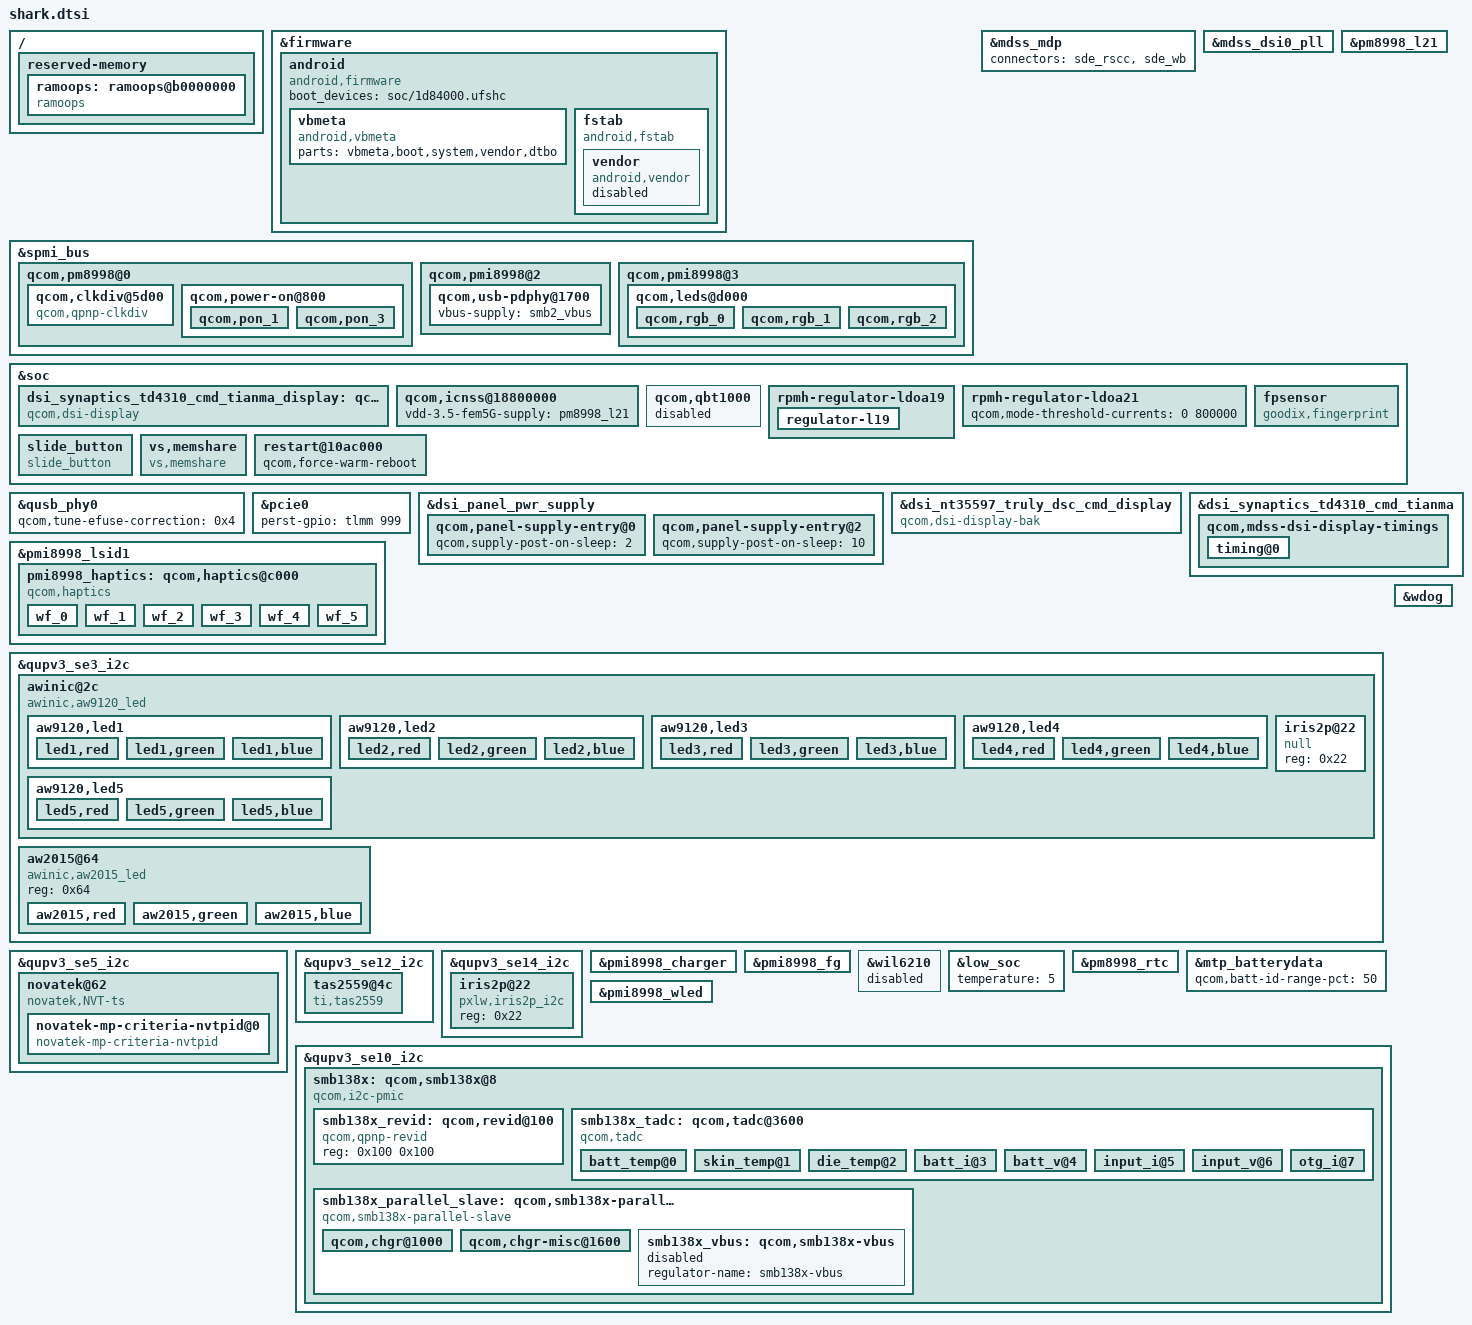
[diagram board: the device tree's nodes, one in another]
/*
 * Copyright (c) 2017, The Linux Foundation. All rights reserved.
 * Copyright (C) 2019 XiaoMi, Inc.
 *
 * This program is free software; you can redistribute it and/or modify
 * it under the terms of the GNU General Public License version 2 and
 * only version 2 as published by the Free Software Foundation.
 *
 * This program is distributed in the hope that it will be useful,
 * but WITHOUT ANY WARRANTY; without even the implied warranty of
 * MERCHANTABILITY or FITNESS FOR A PARTICULAR PURPOSE.  See the
 * GNU General Public License for more details.
 */

#include <dt-bindings/interrupt-controller/irq.h>
#include <dt-bindings/msm/power-on.h>

#include "dsi-panel-synaptics-td4310-video.dtsi"
#include "dsi-panel-synaptics-td4310-cmd.dtsi"

#include "shark-audio-overlay.dtsi"
#include "shark-pinctrl.dtsi"

/ {
	reserved-memory {
		ramoops: ramoops@b0000000 {
			compatible = "ramoops";
			reg = <0 0xb0000000 0 0x00400000>;
			record-size = <0x40000>; /*256x1024*/
			console-size = <0x40000>;
			ftrace-size = <0x40000>;
			pmsg-size = <0x200000>;
			ecc-size = <0x0>;
		};
	};
};

&firmware {
	android {
		compatible = "android,firmware";
		boot_devices = "soc/1d84000.ufshc";
		vbmeta {
			compatible = "android,vbmeta";
			parts = "vbmeta,boot,system,vendor,dtbo";
		};

		fstab {
			compatible = "android,fstab";
			vendor {
				compatible = "android,vendor";
				dev = "/dev/block/platform/soc/1d84000.ufshc/by-name/vendor";
				type = "ext4";
				mnt_flags = "ro,barrier=1,discard";
				fsmgr_flags = "wait,slotselect,avb";
				status = "disabled";
			};
		};
	};
};

&spmi_bus {
	qcom,pm8998@0 {
		qcom,clkdiv@5d00 {
			compatible = "qcom,qpnp-clkdiv";
			reg = <0x5d00 0x100>;
			#clock-cells = <1>;
			qcom,cxo-freq = <19200000>;
			qcom,clkdiv-id = <3>;
			qcom,clkdiv-init-freq = <19200000>;
		};

		qcom,power-on@800 {
			interrupt-names = "kpdpwr", "resin", "kpdpwr-bark",
							  "resin-bark", "kpdpwr-resin-bark";
			interrupts = <0x0 0x8 0x0 IRQ_TYPE_NONE>,
						 <0x0 0x8 0x1 IRQ_TYPE_NONE>,
						 <0x0 0x8 0x3 IRQ_TYPE_NONE>,
						 <0x0 0x8 0x4 IRQ_TYPE_NONE>,
						 <0x0 0x8 0x5 IRQ_TYPE_NONE>;
			
			qcom,pon_1 {
				qcom,support-reset = <1>;
 				qcom,s1-timer = <6720>;
 				qcom,s2-timer = <2000>;
 				qcom,s2-type = <PON_POWER_OFF_HARD_RESET>;
 				qcom,use-bark;
			};

			qcom,pon_3 {
				qcom,s1-timer = <4480>;
 				qcom,s2-timer = <1000>;
 				qcom,s2-type = <PON_POWER_OFF_DVDD_SHUTDOWN>;
			};
		};
	};

	/* shark vbus change to pmi supply */
	qcom,pmi8998@2 {
		qcom,usb-pdphy@1700 {
			vbus-supply = <&smb2_vbus>;
		};
	};

	qcom,pmi8998@3 {
		qcom,leds@d000 {
			qcom,rgb_0 {
				linux,name = "red";
				qcom,default-state = "off";
				linux,default-trigger = "none";
				qcom,start-idx = <0>;
				qcom,idx-len = <48>;
				qcom,turn-off-delay-ms = <500>;
				qcom,duty-pcts =
					[00 00 01 02 03 04 05 06 07 08 09 08 07 06 05 04 03 02 01 00 00 00 00 00
					00 00 00 00 00 00 00 00 00 00 00 00 00 00 00 00 00 00 00 00 00 00 00 00];
				qcom,use-blink;
				qcom,lut-flags = <3>;
				qcom,pause-lo = <0>;
				qcom,pause-hi = <0>;
				qcom,ramp-step-ms = <100>;
				qcom,pwm-us = <1000>;
				qcom,max-current = <12>;
			};

			qcom,rgb_1 {
				linux,name = "green";
				qcom,default-state = "off";
				linux,default-trigger = "none";
				qcom,start-idx = <0>;
				qcom,idx-len = <48>;
				qcom,turn-off-delay-ms = <500>;
				qcom,duty-pcts =
					[00 00 01 02 03 04 05 06 07 08 09 08 07 06 05 04 03 02 01 00 00 00 00 00
					00 00 00 00 00 00 00 00 00 00 00 00 00 00 00 00 00 00 00 00 00 00 00 00];
				qcom,use-blink;
				qcom,lut-flags = <3>;
				qcom,pause-lo = <0>;
				qcom,pause-hi = <0>;
				qcom,ramp-step-ms = <100>;
				qcom,pwm-us = <1000>;
				qcom,max-current = <12>;
			};

			qcom,rgb_2 {
				linux,name = "blue";
				qcom,default-state = "off";
				linux,default-trigger = "none";
				qcom,start-idx = <0>;
				qcom,idx-len = <48>;
				qcom,turn-off-delay-ms = <500>;
				qcom,duty-pcts =
					[00 00 01 02 03 04 05 06 07 08 09 08 07 06 05 04 03 02 01 00 00 00 00 00
					00 00 00 00 00 00 00 00 00 00 00 00 00 00 00 00 00 00 00 00 00 00 00 00];
				qcom,use-blink;
				qcom,lut-flags = <3>;
				qcom,pause-lo = <0>;
				qcom,pause-hi = <0>;
				qcom,ramp-step-ms = <100>;
				qcom,pwm-us = <1000>;
				qcom,max-current = <12>;
			};
		};
	};
};

&mdss_mdp {
	connectors = <&sde_rscc &sde_wb>;
};

&mdss_dsi0_pll {
	qcom,ssc-frequency-hz = <30000>;
	qcom,ssc-ppm = <5000>;
};

&pm8998_l21 {
	regulator-min-microvolt = <3500000>;
	regulator-max-microvolt = <3500000>;
	qcom,init-voltage = <3500000>;
};

&soc {
	dsi_synaptics_td4310_cmd_tianma_display: qcom,dsi-display@29 {
		compatible = "qcom,dsi-display";
		label = "dsi_synap_cmd_tianma_display";
		qcom,display-type = "primary";
		qcom,dsi-ctrl = <&mdss_dsi0>;
		qcom,dsi-phy = <&mdss_dsi_phy0>;
		clocks = <&mdss_dsi0_pll BYTECLK_MUX_0_CLK>,
				<&mdss_dsi0_pll PCLK_MUX_0_CLK>, <&pm8998_div_clk3 0>;
		clock-names = "mux_byte_clk", "mux_pixel_clk", "div_clk3";
		pinctrl-names = "panel_active", "panel_suspend", "default";
		pinctrl-0 = <&sde_dsi_active &sde_te_active>;
		pinctrl-1 = <&sde_dsi_suspend &sde_te_suspend>;
		pinctrl-2 = <&clk_out_default>;
		qcom,dsi-panel = <&dsi_synaptics_td4310_cmd_tianma>;
		vddio-supply = <&pm8998_l14>;
		lab-supply = <&lab_regulator>;
		ibb-supply = <&ibb_regulator>;
	};

	qcom,icnss@18800000 {
		vdd-3.5-fem5G-supply = <&pm8998_l21>;
	};

	qcom,qbt1000 {
		status = "disabled";
	};

	rpmh-regulator-ldoa19 {
		regulator-l19 {
			regulator-max-microvolt = <3310000>;
			qcom,init-voltage = <3100000>;
			regulator-always-on;
		};
	};

	rpmh-regulator-ldoa21 {
		qcom,mode-threshold-currents = <0 800000>;
	};

	fpsensor {
		status = "ok";
		compatible = "goodix,fingerprint";
		vdd_io-supply  = <&pm8998_l19>;
		fp,gpio_rst    = <&tlmm 128 0x00>;
		fp,gpio_irq    = <&tlmm 121 0x00>;
		interrupt-parent = <&tlmm>;
		interrupts = <121 0x0>;
    };

	slide_button {
		compatible = "slide_button";

		pinctrl-names = "default";
		pinctrl-0 = <&slide_button_default>;

		slide-button,gpios = <&tlmm 119 0>;
		debounce-interval = <15>;
		slide-button,wakeup;
	};

	vs,memshare {
		compatible = "vs,memshare";
	};

	restart@10ac000 {
		qcom,force-warm-reboot;
	};
};

&qusb_phy0 {
	qcom,tune-efuse-correction = <0x4>;
};

&pcie0 {
	// hack
	perst-gpio = <&tlmm 999 0>;
};

&dsi_panel_pwr_supply {
	qcom,panel-supply-entry@0 {
		qcom,supply-post-on-sleep = <2>;
	};

	qcom,panel-supply-entry@2 {
		qcom,supply-post-on-sleep = <10>;
	};
};

&mdss_mdp {
	/delete-property/ qcom,sde-has-idle-pc;
};

&dsi_nt35597_truly_dsc_cmd_display {
	compatible = "qcom,dsi-display-bak";
	/delete-property/ qcom,dsi-display-active;
};

&dsi_synaptics_td4310_cmd_tianma_display {
	qcom,dsi-display-active;
};

&dsi_synaptics_td4310_cmd_tianma {
        qcom,mdss-dsi-t-clk-post = <0x0E>;
        qcom,mdss-dsi-t-clk-pre = <0x34>;
        qcom,panel-supply-entries = <&dsi_panel_pwr_supply>;
        qcom,mdss-dsi-bl-pmic-control-type = "bl_ctrl_wled";
        qcom,mdss-dsi-bl-min-level = <1>;
        qcom,mdss-dsi-bl-max-level = <4095>;
        qcom,mdss-brightness-max-level = <4095>;
        qcom,platform-te-gpio = <&tlmm 10 0>;
        qcom,platform-reset-gpio = <&tlmm 94 0>;
        qcom,dsp-reset-gpio = <&tlmm 51 0>;
        qcom,dsp-dsp_1v1 = <&tlmm 37 0>;
        qcom,mdss-dsi-mode-sel-gpio-state = "single_port";

        qcom,mdss-dsi-panel-status-check-mode = "reg_read";
        qcom,mdss-dsi-panel-status-command = [06 01 00 01 00 00 01 0a];
        qcom,mdss-dsi-panel-status-command-state = "dsi_hs_mode";
        qcom,mdss-dsi-panel-status-value = <0x9c>;
        qcom,mdss-dsi-panel-on-check-value = <0x9c>;
        qcom,mdss-dsi-panel-status-read-length = <1>;
		qcom,esd-check-enabled;

		qcom,mdss-dsi-display-timings {
			timing@0{
				qcom,mdss-dsi-panel-phy-timings = [00 22 08 09 25 23 09 09 06 03 04 00];
				qcom,display-topology = <1 0 1>,
										<1 0 2>;
				qcom,default-topology-index = <0>;
			};
		};
};

&pmi8998_lsid1 {
	pmi8998_haptics: qcom,haptics@c000 {
		compatible = "qcom,haptics";
		reg = <0xc000 0x100>;
		interrupts = <0x3 0xc0 0x0 IRQ_TYPE_EDGE_BOTH>,
				<0x3 0xc0 0x1 IRQ_TYPE_EDGE_BOTH>;
		interrupt-names = "hap-sc-irq", "hap-play-irq";

		qcom,vmax-mv = <2800>;
		qcom,ilim-ma = <800>;
		qcom,play-rate-us = <5252>;

		qcom,actuator-type = "lra";
		qcom,lra-resonance-sig-shape = "sine";
		qcom,lra-auto-resonance-mode = "qwd";
		qcom,lra-allow-variable-play-rate;
		qcom,lra-auto-resonance-disable;

		status = "ok";

		wf_0 {
			/* CLICK */
			qcom,effect-id = <0>;
			qcom,wf-vmax-mv = <2700>;
			qcom,wf-pattern = [7e 7e 7e];
			qcom,wf-brake-pattern = [01 00 01 00];
			qcom,lra-auto-resonance-disable;
			qcom,wf-play-rate-us = <4255>;
		};

		wf_1 {
			/* DOUBLE CLICK */
			qcom,effect-id = <1>;
			qcom,wf-vmax-mv = <2700>;
			qcom,wf-pattern = [7e 7e 02 02 02 02 02 02];
			qcom,wf-repeat-count = <2>;
			qcom,wf-s-repeat-count = <1>;
			qcom,lra-auto-resonance-disable;
			qcom,wf-play-rate-us = <4255>;
		};

		wf_2 {
			/* TICK */
			qcom,effect-id = <2>;
			qcom,wf-vmax-mv = <2600>;
			qcom,wf-pattern = [7e];
			qcom,wf-brake-pattern = [01 00 00 00];
			qcom,lra-auto-resonance-disable;
			qcom,wf-play-rate-us = <4255>;
		};

		wf_3 {
			/* THUD */
			qcom,effect-id = <3>;
			qcom,wf-vmax-mv = <2700>;
			qcom,wf-pattern = [7e 7e 7e];
			qcom,lra-auto-resonance-disable;
			qcom,wf-play-rate-us = <4255>;
		};

		wf_4 {
			/* POP */
			qcom,effect-id = <4>;
			qcom,wf-vmax-mv = <2600>;
			qcom,wf-pattern = [7e];
			qcom,wf-brake-pattern = [01 00 01 00];
			qcom,lra-auto-resonance-disable;
			qcom,wf-play-rate-us = <4255>;
		};

		wf_5 {
			/* HEAVY CLICK */
			qcom,effect-id = <5>;
			qcom,wf-vmax-mv = <3100>;
			qcom,wf-pattern = [7e 7e 7e 7e 02 02 7e 7e];
			qcom,lra-auto-resonance-disable;
			qcom,wf-play-rate-us = <4155>;
		};
	};
};

&qupv3_se3_i2c {
    status = "ok";
    awinic@2c {
        compatible = "awinic,aw9120_led";
        reg = <0x2c>;

        pinctrl-names = "awinic_pin_active",
						"awinic_pin_suspend";
        pinctrl-0 = <&aw9120_pdn_gpio_active>;
        pinctrl-1 = <&aw9120_pdn_gpio_suspend>;

		awinic,pdn-gpio = <&tlmm 39 0x00>;
        aw9120,pwm-freq = <245>;
        aw9120,dimming-mode = "loge";

        aw9120,led1 {
            led1,red {
                aw9120,name = "led1:red";
                aw9120,id = <0>;
                aw9120,max-brightness = <255>;
                aw9120,max-current = <17>;
            };
            led1,green {
                aw9120,name = "led1:green";
                aw9120,id = <1>;
                aw9120,max-brightness = <255>;
                aw9120,max-current = <17>;
            };
            led1,blue {
                aw9120,name = "led1:blue";
                aw9120,id = <2>;
                aw9120,max-brightness = <255>;
                aw9120,max-current = <17>;
            };
        };

        aw9120,led2 {
            led2,red {
                aw9120,name = "led2:red";
                aw9120,id = <3>;
                aw9120,max-brightness = <255>;
                aw9120,max-current = <17>;
            };

            led2,green {
                aw9120,name = "led2:green";
                aw9120,id = <4>;
                aw9120,max-brightness = <255>;
                aw9120,max-current = <17>;
            };

            led2,blue {
                aw9120,name = "led2:blue";
                aw9120,id = <5>;
                aw9120,max-brightness = <255>;
                aw9120,max-current = <17>;
            };
        };

        aw9120,led3 {
            led3,red {
                aw9120,name = "led3:red";
                aw9120,id = <6>;
                aw9120,max-brightness = <255>;
                aw9120,max-current = <17>;
            };

            led3,green {
                aw9120,name = "led3:green";
                aw9120,id = <7>;
                aw9120,max-brightness = <255>;
                aw9120,max-current = <17>;
            };
			
            led3,blue {
                aw9120,name = "led3:blue";
                aw9120,id = <15>;
                aw9120,max-brightness = <255>;
                aw9120,max-current = <17>;
            };
        };

        aw9120,led4 {
            led4,red {
                aw9120,name = "led4:red";
                aw9120,id = <9>;
                aw9120,max-brightness = <255>;
                aw9120,max-current = <17>;
            };

            led4,green {
                aw9120,name = "led4:green";
                aw9120,id = <10>;
                aw9120,max-brightness = <255>;
                aw9120,max-current = <17>;
            };

            led4,blue {
                aw9120,name = "led4:blue";
                aw9120,id = <11>;
                aw9120,max-brightness = <255>;
                aw9120,max-current = <17>;
            };
        };

        aw9120,led5 {
            led5,red {
                aw9120,name = "led5:red";
                aw9120,id = <12>;
                aw9120,max-brightness = <255>;
                aw9120,max-current = <17>;
            };

            led5,green {
                aw9120,name = "led5:green";
                aw9120,id = <13>;
                aw9120,max-brightness = <255>;
                aw9120,max-current = <17>;
            };

            led5,blue {
                aw9120,name = "led5:blue";
                aw9120,id = <14>;
                aw9120,max-brightness = <255>;
                aw9120,max-current = <17>;
            };
        };

        iris2p@22 {
                compatible = "null";
                reg = <0x22>;
        };
    };

	aw2015@64 {
		compatible = "awinic,aw2015_led";
		reg = <0x64>;

		aw2015,red {
			aw2015,name = "red";
			aw2015,id = <0>;
			aw2015,imax = <2>;
			aw2015,led-current = <255>;
			aw2015,max-brightness = <255>;
			aw2015,rise-time-ms = <6>;
			aw2015,hold-time-ms = <0>;
			aw2015,fall-time-ms = <6>;
			aw2015,off-time-ms = <4>;
		};

		aw2015,green {
			aw2015,name = "green";
			aw2015,id = <1>;
			aw2015,imax = <2>;
			aw2015,led-current = <255>;
			aw2015,max-brightness = <255>;
			aw2015,rise-time-ms = <6>;
			aw2015,hold-time-ms = <0>;
			aw2015,fall-time-ms = <6>;
			aw2015,off-time-ms = <4>;
		};

		aw2015,blue {
			aw2015,name = "blue";
			aw2015,id = <2>;
			aw2015,imax = <2>;
			aw2015,led-current = <255>;
			aw2015,max-brightness = <255>;
			aw2015,rise-time-ms = <6>;
			aw2015,hold-time-ms = <0>;
			aw2015,fall-time-ms = <6>;
			aw2015,off-time-ms = <4>;
		};
	};
};


&qupv3_se5_i2c {
	status = "okay";

	novatek@62 {
		compatible = "novatek,NVT-ts";
		reg = <0x62>;
		status = "ok";

		avdd-supply = <&pm8998_l14>;

		novatek,reset-gpio = <&tlmm 89 0x00>;
		novatek,irq-gpio = <&tlmm 125 0x2001>;

		novatek,button-keys = <0x244 158>;

		novatek-mp-criteria-nvtpid@0 {
			#address-cells = <1>;
			#size-cells = <0>;
			compatible = "novatek-mp-criteria-nvtpid";

			IC_X_CFG_SIZE = <18>;
			IC_Y_CFG_SIZE = <32>;
			IC_KEY_CFG_SIZE = <4>;
			X_Channel = <18>;
			Y_Channel = <30>;
			AIN_X = <17 16 15 14 13 12 11 10 9 8 7 6 5 4 3 2 1 0>;
			AIN_Y = <0xFF 0xFF 29 28 27 26 25 24 23 22 21 20 19 18 17 16 15
								14 13 12 11 10 9 8 7 6 5 4 3 2 1 0>;
			AIN_KEY = <0 1 2 0xFF>;

			PS_Config_Lmt_Short_Rawdata_P = <20000>;
			PS_Config_Lmt_Short_Rawdata_N = <11550>;
			PS_Config_Lmt_Key_Short_Rawdata_P = <20000>;
			PS_Config_Lmt_Key_Short_Rawdata_N = <11550>;
			PS_Config_Lmt_Short_Diff_P = <6300>;
			PS_Config_Lmt_Short_Diff_N = <0>;
			PS_Config_Lmt_Key_Short_Diff_P = <6300>;
			PS_Config_Lmt_Key_Short_Diff_N = <0>;
			PS_Config_Lmt_Short_Base_P = <2000>;
			PS_Config_Lmt_Short_Base_N = <(-2000)>;
			PS_Config_Lmt_Key_Short_Base_P = <2000>;
			PS_Config_Lmt_Key_Short_Base_N = <(-2000)>;

			PS_Config_Lmt_Open_Rawdata_P = <
				13000 13000 13000 13000 13000 13000 13000 13000 13000 13000 13000 13000 13000 13000 13000 13000 13000 13000
				13000 13000 13000 13000 13000 13000 13000 13000 13000 13000 13000 13000 13000 13000 13000 13000 13000 13000
				13000 13000 13000 13000 13000 13000 13000 13000 13000 13000 13000 13000 13000 13000 13000 13000 13000 13000
				13000 13000 13000 13000 13000 13000 13000 13000 13000 13000 13000 13000 13000 13000 13000 13000 13000 13000
				13000 13000 13000 13000 13000 13000 13000 13000 13000 13000 13000 13000 13000 13000 13000 13000 13000 13000
				13000 13000 13000 13000 13000 13000 13000 13000 13000 13000 13000 13000 13000 13000 13000 13000 13000 13000
				13000 13000 13000 13000 13000 13000 13000 13000 13000 13000 13000 13000 13000 13000 13000 13000 13000 13000
				13000 13000 13000 13000 13000 13000 13000 13000 13000 13000 13000 13000 13000 13000 13000 13000 13000 13000
				13000 13000 13000 13000 13000 13000 13000 13000 13000 13000 13000 13000 13000 13000 13000 13000 13000 13000
				13000 13000 13000 13000 13000 13000 13000 13000 13000 13000 13000 13000 13000 13000 13000 13000 13000 13000
				13000 13000 13000 13000 13000 13000 13000 13000 13000 13000 13000 13000 13000 13000 13000 13000 13000 13000
				13000 13000 13000 13000 13000 13000 13000 13000 13000 13000 13000 13000 13000 13000 13000 13000 13000 13000
				13000 13000 13000 13000 13000 13000 13000 13000 13000 13000 13000 13000 13000 13000 13000 13000 13000 13000
				13000 13000 13000 13000 13000 13000 13000 13000 13000 13000 13000 13000 13000 13000 13000 13000 13000 13000
				13000 13000 13000 13000 13000 13000 13000 13000 13000 13000 13000 13000 13000 13000 13000 13000 13000 13000
				13000 13000 13000 13000 13000 13000 13000 13000 13000 13000 13000 13000 13000 13000 13000 13000 13000 13000
				13000 13000 13000 13000 13000 13000 13000 13000 13000 13000 13000 13000 13000 13000 13000 13000 13000 13000
				13000 13000 13000 13000 13000 13000 13000 13000 13000 13000 13000 13000 13000 13000 13000 13000 13000 13000
				13000 13000 13000 13000 13000 13000 13000 13000 13000 13000 13000 13000 13000 13000 13000 13000 13000 13000
				13000 13000 13000 13000 13000 13000 13000 13000 13000 13000 13000 13000 13000 13000 13000 13000 13000 13000
				13000 13000 13000 13000 13000 13000 13000 13000 13000 13000 13000 13000 13000 13000 13000 13000 13000 13000
				13000 13000 13000 13000 13000 13000 13000 13000 13000 13000 13000 13000 13000 13000 13000 13000 13000 13000
				13000 13000 13000 13000 13000 13000 13000 13000 13000 13000 13000 13000 13000 13000 13000 13000 13000 13000
				13000 13000 13000 13000 13000 13000 13000 13000 13000 13000 13000 13000 13000 13000 13000 13000 13000 13000
				13000 13000 13000 13000 13000 13000 13000 13000 13000 13000 13000 13000 13000 13000 13000 13000 13000 13000
				13000 13000 13000 13000 13000 13000 13000 13000 13000 13000 13000 13000 13000 13000 13000 13000 13000 13000
				13000 13000 13000 13000 13000 13000 13000 13000 13000 13000 13000 13000 13000 13000 13000 13000 13000 13000
				13000 13000 13000 13000 13000 13000 13000 13000 13000 13000 13000 13000 13000 13000 13000 13000 13000 13000
				13000 13000 13000 13000 13000 13000 13000 13000 13000 13000 13000 13000 13000 13000 13000 13000 13000 13000
				13000 13000 13000 13000 13000 13000 13000 13000 13000 13000 13000 13000 13000 13000 13000 13000 13000 13000
				13000 13000 13000>;

			PS_Config_Lmt_Open_Rawdata_N = <
				6500 6500 6500 6500 6500 6500 6500 6500 6500 6500 6500 6500 6500 6500 6500 6500 6500 6500
				6500 6500 6500 6500 6500 6500 6500 6500 6500 6500 6500 6500 6500 6500 6500 6500 6500 6500
				6500 6500 6500 6500 6500 6500 6500 6500 6500 6500 6500 6500 6500 6500 6500 6500 6500 6500
				6500 6500 6500 6500 6500 6500 6500 6500 6500 6500 6500 6500 6500 6500 6500 6500 6500 6500
				6500 6500 6500 6500 6500 6500 6500 6500 6500 6500 6500 6500 6500 6500 6500 6500 6500 6500
				6500 6500 6500 6500 6500 6500 6500 6500 6500 6500 6500 6500 6500 6500 6500 6500 6500 6500
				6500 6500 6500 6500 6500 6500 6500 6500 6500 6500 6500 6500 6500 6500 6500 6500 6500 6500
				6500 6500 6500 6500 6500 6500 6500 6500 6500 6500 6500 6500 6500 6500 6500 6500 6500 6500
				6500 6500 6500 6500 6500 6500 6500 6500 6500 6500 6500 6500 6500 6500 6500 6500 6500 6500
				6500 6500 6500 6500 6500 6500 6500 6500 6500 6500 6500 6500 6500 6500 6500 6500 6500 6500
				6500 6500 6500 6500 6500 6500 6500 6500 6500 6500 6500 6500 6500 6500 6500 6500 6500 6500
				6500 6500 6500 6500 6500 6500 6500 6500 6500 6500 6500 6500 6500 6500 6500 6500 6500 6500
				6500 6500 6500 6500 6500 6500 6500 6500 6500 6500 6500 6500 6500 6500 6500 6500 6500 6500
				6500 6500 6500 6500 6500 6500 6500 6500 6500 6500 6500 6500 6500 6500 6500 6500 6500 6500
				6500 6500 6500 6500 6500 6500 6500 6500 6500 6500 6500 6500 6500 6500 6500 6500 6500 6500
				6500 6500 6500 6500 6500 6500 6500 6500 6500 6500 6500 6500 6500 6500 6500 6500 6500 6500
				6500 6500 6500 6500 6500 6500 6500 6500 6500 6500 6500 6500 6500 6500 6500 6500 6500 6500
				6500 6500 6500 6500 6500 6500 6500 6500 6500 6500 6500 6500 6500 6500 6500 6500 6500 6500
				6500 6500 6500 6500 6500 6500 6500 6500 6500 6500 6500 6500 6500 6500 6500 6500 6500 6500
				6500 6500 6500 6500 6500 6500 6500 6500 6500 6500 6500 6500 6500 6500 6500 6500 6500 6500
				6500 6500 6500 6500 6500 6500 6500 6500 6500 6500 6500 6500 6500 6500 6500 6500 6500 6500
				6500 6500 6500 6500 6500 6500 6500 6500 6500 6500 6500 6500 6500 6500 6500 6500 6500 6500
				6500 6500 6500 6500 6500 6500 6500 6500 6500 6500 6500 6500 6500 6500 6500 6500 6500 6500
				6500 6500 6500 6500 6500 6500 6500 6500 6500 6500 6500 6500 6500 6500 6500 6500 6500 6500
				6500 6500 6500 6500 6500 6500 6500 6500 6500 6500 6500 6500 6500 6500 6500 6500 6500 6500
				6500 6500 6500 6500 6500 6500 6500 6500 6500 6500 6500 6500 6500 6500 6500 6500 6500 6500
				6500 6500 6500 6500 6500 6500 6500 6500 6500 6500 6500 6500 6500 6500 6500 6500 6500 6500
				6500 6500 6500 6500 6500 6500 6500 6500 6500 6500 6500 6500 6500 6500 6500 6500 6500 6500
				6500 6500 6500 6500 6500 6500 6500 6500 6500 6500 6500 6500 6500 6500 6500 6500 6500 6500
				6500 6500 6500 6500 6500 6500 6500 6500 6500 6500 6500 6500 6500 6500 6500 6500 6500 6500
				6500 6500 6500>;

			PS_Config_Lmt_FW_Rawdata_P = <
				2000 2000 2000 2000 2000 2000 2000 2000 2000 2000 2000 2000 2000 2000 2000 2000 2000 2000
				2000 2000 2000 2000 2000 2000 2000 2000 2000 2000 2000 2000 2000 2000 2000 2000 2000 2000
				2000 2000 2000 2000 2000 2000 2000 2000 2000 2000 2000 2000 2000 2000 2000 2000 2000 2000
				2000 2000 2000 2000 2000 2000 2000 2000 2000 2000 2000 2000 2000 2000 2000 2000 2000 2000
				2000 2000 2000 2000 2000 2000 2000 2000 2000 2000 2000 2000 2000 2000 2000 2000 2000 2000
				2000 2000 2000 2000 2000 2000 2000 2000 2000 2000 2000 2000 2000 2000 2000 2000 2000 2000
				2000 2000 2000 2000 2000 2000 2000 2000 2000 2000 2000 2000 2000 2000 2000 2000 2000 2000
				2000 2000 2000 2000 2000 2000 2000 2000 2000 2000 2000 2000 2000 2000 2000 2000 2000 2000
				2000 2000 2000 2000 2000 2000 2000 2000 2000 2000 2000 2000 2000 2000 2000 2000 2000 2000
				2000 2000 2000 2000 2000 2000 2000 2000 2000 2000 2000 2000 2000 2000 2000 2000 2000 2000
				2000 2000 2000 2000 2000 2000 2000 2000 2000 2000 2000 2000 2000 2000 2000 2000 2000 2000
				2000 2000 2000 2000 2000 2000 2000 2000 2000 2000 2000 2000 2000 2000 2000 2000 2000 2000
				2000 2000 2000 2000 2000 2000 2000 2000 2000 2000 2000 2000 2000 2000 2000 2000 2000 2000
				2000 2000 2000 2000 2000 2000 2000 2000 2000 2000 2000 2000 2000 2000 2000 2000 2000 2000
				2000 2000 2000 2000 2000 2000 2000 2000 2000 2000 2000 2000 2000 2000 2000 2000 2000 2000
				2000 2000 2000 2000 2000 2000 2000 2000 2000 2000 2000 2000 2000 2000 2000 2000 2000 2000
				2000 2000 2000 2000 2000 2000 2000 2000 2000 2000 2000 2000 2000 2000 2000 2000 2000 2000
				2000 2000 2000 2000 2000 2000 2000 2000 2000 2000 2000 2000 2000 2000 2000 2000 2000 2000
				2000 2000 2000 2000 2000 2000 2000 2000 2000 2000 2000 2000 2000 2000 2000 2000 2000 2000
				2000 2000 2000 2000 2000 2000 2000 2000 2000 2000 2000 2000 2000 2000 2000 2000 2000 2000
				2000 2000 2000 2000 2000 2000 2000 2000 2000 2000 2000 2000 2000 2000 2000 2000 2000 2000
				2000 2000 2000 2000 2000 2000 2000 2000 2000 2000 2000 2000 2000 2000 2000 2000 2000 2000
				2000 2000 2000 2000 2000 2000 2000 2000 2000 2000 2000 2000 2000 2000 2000 2000 2000 2000
				2000 2000 2000 2000 2000 2000 2000 2000 2000 2000 2000 2000 2000 2000 2000 2000 2000 2000
				2000 2000 2000 2000 2000 2000 2000 2000 2000 2000 2000 2000 2000 2000 2000 2000 2000 2000
				2000 2000 2000 2000 2000 2000 2000 2000 2000 2000 2000 2000 2000 2000 2000 2000 2000 2000
				2000 2000 2000 2000 2000 2000 2000 2000 2000 2000 2000 2000 2000 2000 2000 2000 2000 2000
				2000 2000 2000 2000 2000 2000 2000 2000 2000 2000 2000 2000 2000 2000 2000 2000 2000 2000
				2000 2000 2000 2000 2000 2000 2000 2000 2000 2000 2000 2000 2000 2000 2000 2000 2000 2000
				2000 2000 2000 2000 2000 2000 2000 2000 2000 2000 2000 2000 2000 2000 2000 2000 2000 2000
				2000 2000 2000>;

			PS_Config_Lmt_FW_Rawdata_N= <
				400 400 400 400 400 400 400 400 400 400 400 400 400 400 400 400 400 400
				400 400 400 400 400 400 400 400 400 400 400 400 400 400 400 400 400 400
				400 400 400 400 400 400 400 400 400 400 400 400 400 400 400 400 400 400
				400 400 400 400 400 400 400 400 400 400 400 400 400 400 400 400 400 400
				400 400 400 400 400 400 400 400 400 400 400 400 400 400 400 400 400 400
				400 400 400 400 400 400 400 400 400 400 400 400 400 400 400 400 400 400
				400 400 400 400 400 400 400 400 400 400 400 400 400 400 400 400 400 400
				400 400 400 400 400 400 400 400 400 400 400 400 400 400 400 400 400 400
				400 400 400 400 400 400 400 400 400 400 400 400 400 400 400 400 400 400
				400 400 400 400 400 400 400 400 400 400 400 400 400 400 400 400 400 400
				400 400 400 400 400 400 400 400 400 400 400 400 400 400 400 400 400 400
				400 400 400 400 400 400 400 400 400 400 400 400 400 400 400 400 400 400
				400 400 400 400 400 400 400 400 400 400 400 400 400 400 400 400 400 400
				400 400 400 400 400 400 400 400 400 400 400 400 400 400 400 400 400 400
				400 400 400 400 400 400 400 400 400 400 400 400 400 400 400 400 400 400
				400 400 400 400 400 400 400 400 400 400 400 400 400 400 400 400 400 400
				400 400 400 400 400 400 400 400 400 400 400 400 400 400 400 400 400 400
				400 400 400 400 400 400 400 400 400 400 400 400 400 400 400 400 400 400
				400 400 400 400 400 400 400 400 400 400 400 400 400 400 400 400 400 400
				400 400 400 400 400 400 400 400 400 400 400 400 400 400 400 400 400 400
				400 400 400 400 400 400 400 400 400 400 400 400 400 400 400 400 400 400
				400 400 400 400 400 400 400 400 400 400 400 400 400 400 400 400 400 400
				400 400 400 400 400 400 400 400 400 400 400 400 400 400 400 400 400 400
				400 400 400 400 400 400 400 400 400 400 400 400 400 400 400 400 400 400
				400 400 400 400 400 400 400 400 400 400 400 400 400 400 400 400 400 400
				400 400 400 400 400 400 400 400 400 400 400 400 400 400 400 400 400 400
				400 400 400 400 400 400 400 400 400 400 400 400 400 400 400 400 400 400
				400 400 400 400 400 400 400 400 400 400 400 400 400 400 400 400 400 400
				400 400 400 400 400 400 400 400 400 400 400 400 400 400 400 400 400 400
				400 400 400 400 400 400 400 400 400 400 400 400 400 400 400 400 400 400
				400 400 400>;

			PS_Config_Lmt_FW_CC_P = <38>;
			PS_Config_Lmt_FW_CC_N = <9>;
			PS_Config_Lmt_Key_FW_CC_P = <38>;
			PS_Config_Lmt_Key_FW_CC_N = <9>;

			PS_Config_Lmt_FW_CC_I_P = <25>;
			PS_Config_Lmt_FW_CC_I_N = <0>;
			PS_Config_Lmt_FW_CC_Q_P = <25>;
			PS_Config_Lmt_FW_CC_Q_N = <0>;
			PS_Config_Lmt_Key_FW_CC_I_P = <25>;
			PS_Config_Lmt_Key_FW_CC_I_N = <0>;
			PS_Config_Lmt_Key_FW_CC_Q_P = <25>;
			PS_Config_Lmt_Key_FW_CC_Q_N = <0>;

			PS_Config_Lmt_FW_Diff_P = <35>;
			PS_Config_Lmt_FW_Diff_N = <(-35)>;
			PS_Config_Lmt_Key_FW_Diff_P = <35>;
			PS_Config_Lmt_Key_FW_Diff_N = <(-35)>;

			PS_Config_Diff_Test_Frame = <50>;
		};
	};
};

&qupv3_se12_i2c {
	status = "ok";

    tas2559@4c {
        compatible = "ti,tas2559";
        reg = <0x4c>;

        ti,tas2559-reset-gpio = <&tlmm 79 0x00>;
        ti,tas2560-reset-gpio = <&tlmm 6 0x00>;
        ti,tas2559-irq-gpio = <&tlmm 123 0>;
        ti,tas2560-irq-gpio = <&tlmm 122 0>;

        ti,tas2559-addr = <0x4c>;
        ti,tas2560-addr = <0x4e>;
        ti,tas2559-channel = <0>;
        ti,tas2560-channel = <1>;

        ti,ycrc-enable = <1>;
        ti,echo-ref = <0>;
        ti,bit-rate = <16>;
	};
};

&qupv3_se14_i2c {
	status = "ok";

	iris2p@22 {
		compatible = "pxlw,iris2p_i2c";
		reg = <0x22>;
	};
};

&pmi8998_charger {
	qcom,usb-icl-ua = <2800000>;
	qcom,fcc-max-ua = <3500000>;
	qcom,fv-max-uv =  <4400000>;
	qcom,auto-recharge-soc;

	qcom,sw-jeita-enable;
	qcom,battery-data = <&mtp_batterydata>;

	pinctrl-names = "default";
	pinctrl-0 = <&gpio9_dig_out_default>;
	slave-shdn = <&pm8998_gpios 9 GPIO_ACTIVE_HIGH>;
};

&pmi8998_fg {
	qcom,fg-sys-term-current = <(-400)>;
	qcom,fg-chg-term-current = <120>;

	qcom,fg-recharge-soc-thr = <99>;
	qcom,fg-auto-recharge-soc;
	qcom,hold-soc-while-full;
	qcom,linearize-soc;

	qcom,fg-cutoff-voltage   = <3200>;
	qcom,fg-empty-voltage    = <3000>;
	qcom,fg-cc-cv-threshold-mv = <4390>;

	qcom,fg-jeita-thresholds = <0 15 45 55>;
	qcom,fg-aging-jeita-thresholds = <(-20) 15 45 68>;
	qcom,fg-jeita-hyst-temp  = <2>;
	qcom,fg-batt-temp-delta  = <6>;

	qcom,fg-rsense-sel       = <2>;
	qcom,fg-force-load-profile;
};

&wil6210 {
	status = "disabled";
};

&low_soc {
	temperature = <5>;
};

&pm8998_rtc {
	qcom,qpnp-rtc-write = <1>;
	qcom,qpnp-rtc-alarm-pwrup = <1>;
};

&mtp_batterydata {
	qcom,batt-id-range-pct = <50>;
	#include "batterydata-e30-atl-4000mah.dtsi"
	#include "batterydata-e30-sunwoda-4000mah.dtsi"
	/delete-node/ qcom,itech_3000mah;
	/delete-node/ qcom,ascent_3450mah;
	/delete-node/ qcom,Demo_battery_6000mah;
};

&pmi8998_wled {
	status = "okay";
	qcom,fs-curr-ua = <20000>;
	qcom,led-strings-list = [00 01 02 03];
	qcom,dim-mode = "digtal";
	qcom,en-cabc = <1>;
};

&wdog {
	qcom,bark-time = <20000>;
	qcom,pet-time = <15000>;
};

&qupv3_se10_i2c {
	status = "okay";

	smb138x: qcom,smb138x@8 {
		compatible = "qcom,i2c-pmic";
		reg = <0x8>;
		#address-cells = <1>;
		#size-cells = <1>;
		interrupt-parent = <&spmi_bus>;
		interrupts = <0x0 0xd1 0x0 IRQ_TYPE_LEVEL_LOW>;
		interrupt_names = "smb138x";
		interrupt-controller;
		#interrupt-cells = <3>;
		qcom,periph-map = <0x10 0x11 0x12 0x13 0x14 0x16 0x36>;

		smb138x_revid: qcom,revid@100 {
			compatible = "qcom,qpnp-revid";
			reg = <0x100 0x100>;
		};

		smb138x_tadc: qcom,tadc@3600 {
			compatible = "qcom,tadc";
			reg = <0x3600 0x100>;
			#address-cells = <1>;
			#size-cells = <0>;
			#io-channel-cells = <1>;
			interrupt-parent = <&smb138x>;
			interrupts = <0x36 0x0 IRQ_TYPE_EDGE_BOTH>;
			interrupt-names = "eoc";

			batt_temp@0 {
				reg = <0>;
				qcom,rbias = <68100>;
				qcom,rtherm-at-25degc = <68000>;
				qcom,beta-coefficient = <3450>;
			};

			skin_temp@1 {
				reg = <1>;
				qcom,rbias = <33000>;
				qcom,rtherm-at-25degc = <68000>;
				qcom,beta-coefficient = <3450>;
			};

			die_temp@2 {
				reg = <2>;
				qcom,scale = <(-1306)>;
				qcom,offset = <397904>;
			};

			batt_i@3 {
				reg = <3>;
				qcom,channel = <3>;
				qcom,scale = <(-20000000)>;
			};

			batt_v@4 {
				reg = <4>;
				qcom,scale = <5000000>;
			};

			input_i@5 {
				reg = <5>;
				qcom,scale = <14285714>;
			};

			input_v@6 {
				reg = <6>;
				qcom,scale = <25000000>;
			};

			otg_i@7 {
				reg = <7>;
				qcom,scale = <5714286>;
			};
		};

		smb138x_parallel_slave: qcom,smb138x-parallel-slave@1000 {
			compatible = "qcom,smb138x-parallel-slave";
			qcom,pmic-revid = <&smb138x_revid>;
			qcom,parallel-mode = <1>;
			reg = <0x1000 0x700>;
			#address-cells = <1>;
			#size-cells = <1>;
			interrupt-parent = <&smb138x>;

			io-channels =
				<&smb138x_tadc 1>,
				<&smb138x_tadc 2>,
				<&smb138x_tadc 3>,
				<&smb138x_tadc 14>,
				<&smb138x_tadc 15>,
				<&smb138x_tadc 16>,
				<&smb138x_tadc 17>;
			io-channel-names =
				"connector_temp",
				"charger_temp",
				"batt_i",
				"connector_temp_thr1",
				"connector_temp_thr2",
				"connector_temp_thr3",
				"charger_temp_max";

			qcom,chgr@1000 {
				reg = <0x1000 0x100>;
				interrupts = <0x10 0x1 IRQ_TYPE_EDGE_RISING>;
				interrupt-names = "chg-state-change";
			};

			qcom,chgr-misc@1600 {
				reg = <0x1600 0x100>;
				interrupts = <0x16 0x1 IRQ_TYPE_EDGE_RISING>,
					     <0x16 0x6 IRQ_TYPE_EDGE_RISING>;
				interrupt-names = "wdog-bark",
						  "temperature-change";
			};

			smb138x_vbus: qcom,smb138x-vbus {
				status = "disabled";
				regulator-name = "smb138x-vbus";
			};
		};
	};
};
